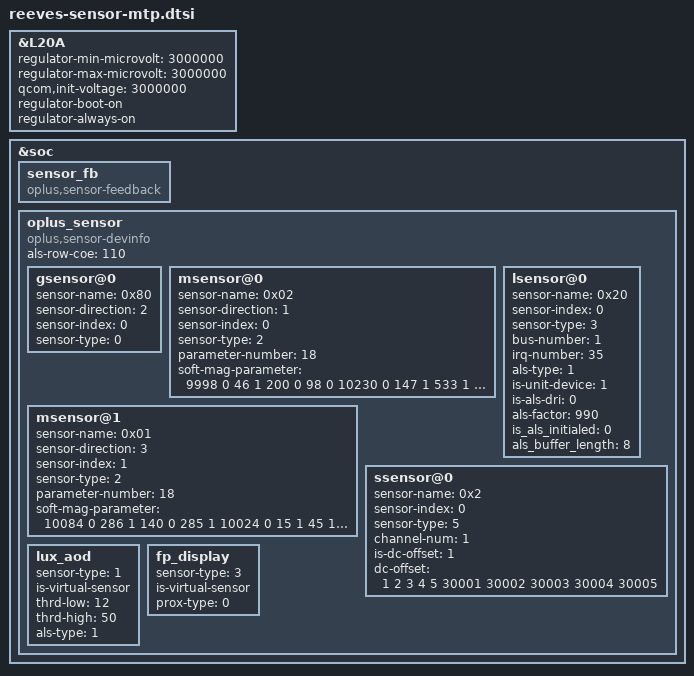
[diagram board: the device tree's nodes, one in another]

&L20A {
			regulator-min-microvolt = <3000000>;
			regulator-max-microvolt = <3000000>;
			qcom,init-voltage = <3000000>;
			regulator-boot-on;
			regulator-always-on;
			status = "okay";
};

&soc {
	sensor_fb {
		compatible = "oplus,sensor-feedback";
	};
	oplus_sensor {
			compatible = "oplus,sensor-devinfo";
			als-row-coe = <110>;
			/*enum {LSM6DSM = 0x01, BMI160 = 0x02, LSM6DS3 = 0x04, BMI260 = 0x08};*/
			gsensor@0 {
					sensor-name = <0x80>;//BMI3X0
					sensor-direction = <2>;
					sensor-index = <0>;//source num
					sensor-type = <0>;//OPLUS_ACCEL
			};
			/* enum {AKM0991X = 0x01, MMC5603 = 0x02, MXG4300 = 0x04};*/
			msensor@0 {
					sensor-name = <0x02>;//MMC5603
					sensor-direction = <1>;
					sensor-index = <0>;
					sensor-type = <2>;//OPPO_MAG
					parameter-number= <18>;
					soft-mag-parameter = <9998 0 46 1 200 0 98 0 10230 0 147 1 533 1 9 0 10752 0>;//e00 sign e01 sign...
			};
			msensor@1 {
					sensor-name = <0x01>;//AKM09918
					sensor-direction = <3>;
					sensor-index = <1>;
					sensor-type = <2>;//OPLUS_MAG
					parameter-number= <18>;
					soft-mag-parameter = <10084 0 286 1 140 0 285 1 10024 0 15 1 45 1 117 1 10273 0>;//e00 sign e01 sign...
			};
			/*enum {STK3A5X=0x01,TCS3701=0x02,TCS3408=0x04,STK326X=0x08,MN78911=0x10};*/
			/*enum {NORMAL=0x01,UNDER_LCD=0x02,VIRTUAL_UNDER_LCD=0x03}*/
			lsensor@0 {
					sensor-name = <0x20>;//STK3329
					sensor-index = <0>;
					sensor-type = <3>;//OPLUS_ALS
					bus-number = <1>;
					irq-number = <35>;
					als-type = <1>;
					is-unit-device = <1>;
					is-als-dri = <0>;
					als-factor = <990>;
					is_als_initialed = <0>;
					als_buffer_length = <8>;
			};
			ssensor@0 {
				sensor-name = <0x2>;//SX9331
				sensor-index = <0>;
				sensor-type = <5>;//OPLUS_SAR
				channel-num = <1>;
				is-dc-offset = <1>;
				dc-offset = <1 2 3 4 5 30001 30002 30003 30004 30005>;
			};
			/*virtual sensor
			enum sensor_algo_id {
					OPPO_PICKUP_DETECT,
					OPPO_LUX_AOD,
					OPPO_TP_GESTURE,
					OPPO_FP_DISPLAY,
					OPPO_FREE_FALL,
					OPPO_CAMERA_PROTECT,
					SENSOR_ALGO_NUM
			}*/
			lux_aod {
					sensor-type = <1>; //OPPO_LUX_AOD
					is-virtual-sensor;
					thrd-low = <12>;
					thrd-high = <50>;
					als-type = <1>; // 0 - wise_light; 1 - ambient_light
			};
			fp_display {
					sensor-type = <3>; //OPPO_FP_DISPLAY
					is-virtual-sensor;
					prox-type = <0>; // 0 - proximity; 1 - proximity_fake
			};
	};
};
